# PY32F040xx register map
Vendor: Puya; Series: PY32F0; File version: 1.0.0
CPU: CM0+ r0p1, little endian, no MPU, no FPU, 4 interrupt priority bits
Registers are 32-bit, read-write, reset 0x0 unless marked. A register's access mark holds for its fields unless they carry their own. Offsets are from the block's base; [hi:lo] are bit positions; lines under a group give offsets from that group; {n}, {i} and the like mark numbered series; 'fields as' and 'values as' point back to an identical list.

## DIV — Hardware Divider
Base 0x40023800
0x00 DEND — Dividend
0x04 SOR — Divisor
0x08 QUOT ro — Quotient
0x0C REMA ro — Remainder
0x10 SIGN — des SIGN
  [0] DIV_SIGN — des DIV_SIGN
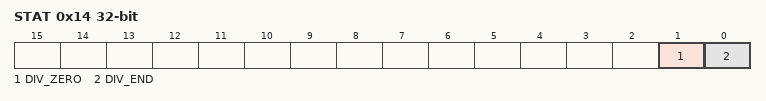
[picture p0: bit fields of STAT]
0x14 STAT — des SIGN
  [1] DIV_ZERO — des DIV_ZERO
  [0] DIV_END — des DIV_END

## DMA — Direct memory access
Base 0x40020000
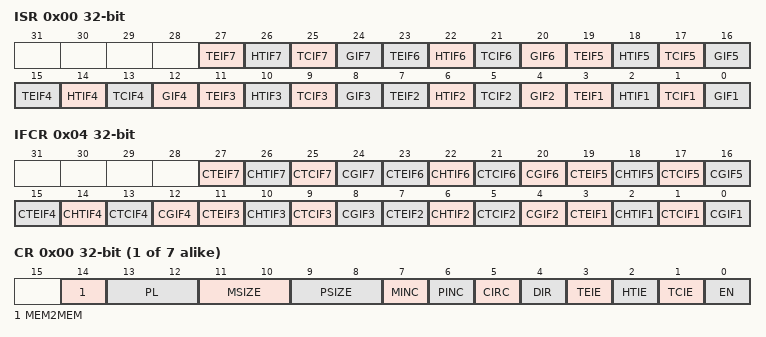
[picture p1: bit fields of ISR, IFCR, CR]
0x00 ISR ro
  [4n-1] TEIF{n} (n=1..7) — Channel {n} Transfer Error flag
    0=NoError (No transfer error); 1=Error (A transfer error has occured)
  [4n-2] HTIF{n} (n=1..7) — Channel {n} Half Transfer Complete flag
    0=NotHalf (No half transfer event); 1=Half (A half transfer event has occured)
  [4n-3] TCIF{n} (n=1..7) — Channel {n} Transfer Complete flag
    0=NotComplete (No transfer complete event); 1=Complete (A transfer complete event has occured)
  [4n-4] GIF{n} (n=1..7) — Channel {n} Global interrupt flag
    0=NoEvent (No transfer error, half event, complete event); 1=Event (A transfer error, half event or complete event has occured)
0x04 IFCR wo
  [4n-1] CTEIF{n} (n=1..7) — Channel {n} Transfer Error clear
    1=Clears the TEIF flag in the ISR register
  [4n-2] CHTIF{n} (n=1..7) — Channel {n} Half Transfer clear
    1=Clears the HTIF flag in the ISR register
  [4n-3] CTCIF{n} (n=1..7) — Channel {n} Transfer Complete clear
    1=Clears the TCIF flag in the ISR register
  [4n-4] CGIF{n} (n=1..7) — Channel {n} Global interrupt clear
    1=Clears the GIF, TEIF, HTIF, TCIF flags in the ISR register
0x08 CH{i} (i=1..7; step 0x14) group — Channel cluster: CCR?, CNDTR?, CPAR?, and CMAR? registers
  0x00 CR — desc CCR1
    [14] MEM2MEM
      0=Disabled (Memory to memory mode disabled); 1=Enabled (Memory to memory mode enabled)
    [13:12] PL
      0=Low (Low priority); 1=Medium priority; 2=High priority; 3=Very high priority
    [11:10] MSIZE
      0=Bits8 (8-bit size); 1=Bits16 (16-bit size); 2=Bits32 (32-bit size)
    [9:8] PSIZE
      values as MSIZE
    [7] MINC
      0=Disabled (Increment mode disabled); 1=Enabled (Increment mode enabled)
    [6] PINC
      values as MINC
    [5] CIRC
      0=Disabled (Circular buffer disabled); 1=Enabled (Circular buffer enabled)
    [4] DIR
      0=FromPeripheral (Read from peripheral); 1=FromMemory (Read from memory)
    [3] TEIE
      0=Disabled (Transfer Error interrupt disabled); 1=Enabled (Transfer Error interrupt enabled)
    [2] HTIE
      0=Disabled (Half Transfer interrupt disabled); 1=Enabled (Half Transfer interrupt enabled)
    [1] TCIE
      0=Disabled (Transfer Complete interrupt disabled); 1=Enabled (Transfer Complete interrupt enabled)
    [0] EN
      0=Disabled (Channel disabled); 1=Enabled (Channel enabled)
  0x04 NDTR — desc CNDTR1
    [15:0] NDT
  0x08 PAR — desc CPAR1
    [31:0] PA
  0x0C MAR — desc CMAR1
    [31:0] MA

## EXTI — External interrupt/event controller
Base 0x40021800
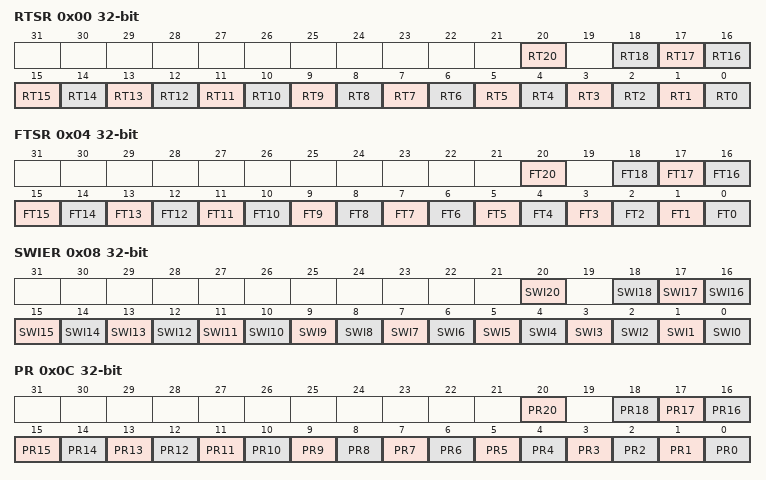
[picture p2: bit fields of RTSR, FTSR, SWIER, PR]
0x00 RTSR — EXTI rising trigger selection register
  [all] fields
    0=Disabled (Rising edge trigger is disabled); 1=Enabled (Rising edge trigger is enabled)
  [20] RT20 — Rising trigger event configuration bit of Configurable Event input
  [n] RT{n} (n=0..18) — Rising trigger event configuration bit of Configurable Event input
0x04 FTSR — EXTI falling trigger selection register
  [all] fields
    0=Disabled (Falling edge trigger is disabled); 1=Enabled (Falling edge trigger is enabled)
  [20] FT20 — Falling trigger event configuration bit of Configurable Event input
  [n] FT{n} (n=0..18) — Falling trigger event configuration bit of Configurable Event input
0x08 SWIER — EXTI software interrupt event register
  [all] fields
    on write: 1=Pend (Generates an interrupt request)
  [20] SWI20 — Rising trigger event configuration bit of Configurable Event input
  [n] SWI{n} (n=0..18) — Rising trigger event configuration bit of Configurable Event input
0x0C PR — EXTI pending register
  [all] fields
    on read: 0=NotPending (No trigger request occurred); 1=Pending (Selected trigger request occurred) | on write: 1=Clears pending bit
  [20] PR20 write-1-clears — configurable event inputs x rising edge Pending bit.
  [n] PR{n} write-1-clears (n=14..18) — configurable event inputs x rising edge Pending bit.
  [13] PR13 write-1-clears — configurable event inputs x rising edge Pending bit
  [n] PR{n} write-1-clears (n=0..12) — configurable event inputs x rising edge Pending bit.
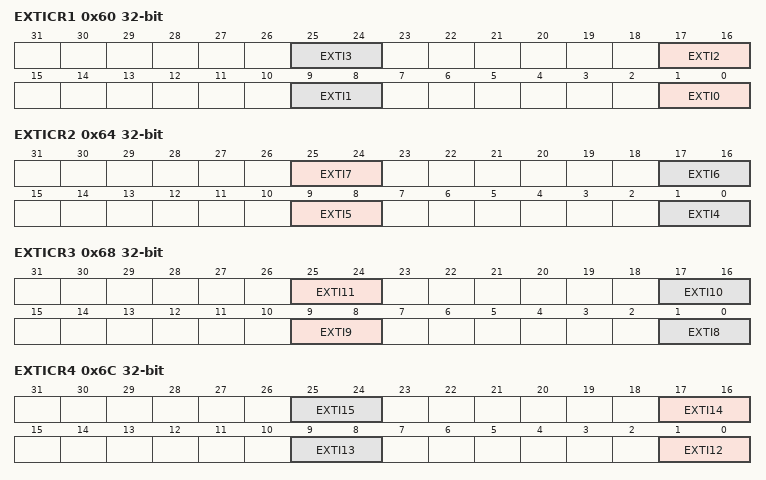
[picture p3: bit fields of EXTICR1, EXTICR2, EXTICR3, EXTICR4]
0x60 EXTICR1 — EXTI external interrupt selection register
  [all] fields
    0=PA (GPIO port A selected); 1=PB (GPIO port B selected); 2=PF (GPIO port F selected)
  [8n+1:8n] EXTI{n} (n=0..3) — GPIO port selection
0x64 EXTICR2 — EXTI external interrupt selection register
  [25:24] EXTI7 — GPIO port selection
    0=PA (GPIO port A selected); 1=PB (GPIO port B selected)
  [17:16] EXTI6 — GPIO port selection
    0=PA (GPIO port A selected); 1=PB (GPIO port B selected)
  [9:8] EXTI5 — GPIO port selection
    0=PA (GPIO port A selected); 1=PB (GPIO port B selected)
  [1:0] EXTI4 — GPIO port selection
    values as the fields of EXTICR1
0x68 EXTICR3 — EXTI external interrupt selection register
  [25:24] EXTI11 — GPIO port selection
  [17:16] EXTI10 — GPIO port selection
  [9:8] EXTI9 — GPIO port selection
  [1:0] EXTI8 — GPIO port selection
    0=PA (GPIO port A selected); 1=PB (GPIO port B selected)
0x6C EXTICR4 — EXTI external interrupt selection register
  [8n-95:8n-96] EXTI{n} (n=12..15) — GPIO port selection
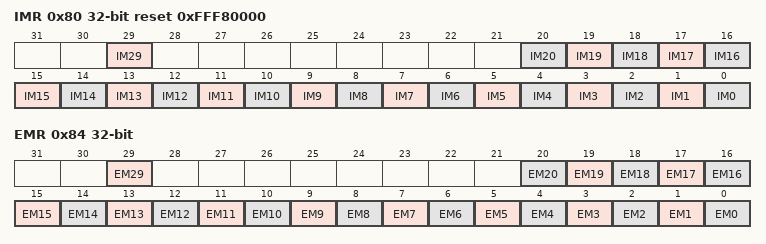
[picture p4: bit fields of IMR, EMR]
0x80 IMR reset 0xFFF80000 — EXTI CPU wakeup with interrupt mask register
  [all] fields
    0=Masked (Interrupt request line is masked); 1=Unmasked (Interrupt request line is unmasked)
  [29] IM29 — CPU wakeup with interrupt mask on event input
  [n] IM{n} (n=0..20) — CPU wakeup with interrupt mask on event input
0x84 EMR — EXTI CPU wakeup with event mask register
  [all] fields
    values as the fields of IMR
  [29] EM29 — CPU wakeup with event mask on event input
  [n] EM{n} (n=0..20) — CPU wakeup with event mask on event input
